# STM32WBA62xx register map
File version: 1.0
Registers are 32-bit, read-write, reset 0x0 unless marked. A register's access mark holds for its fields unless they carry their own. Offsets are from the block's base; [hi:lo] are bit positions; {n}, {i} and the like mark numbered series.

## USB_OTG_HS — USB_OTG_Core_Registers
Base 0x42040000
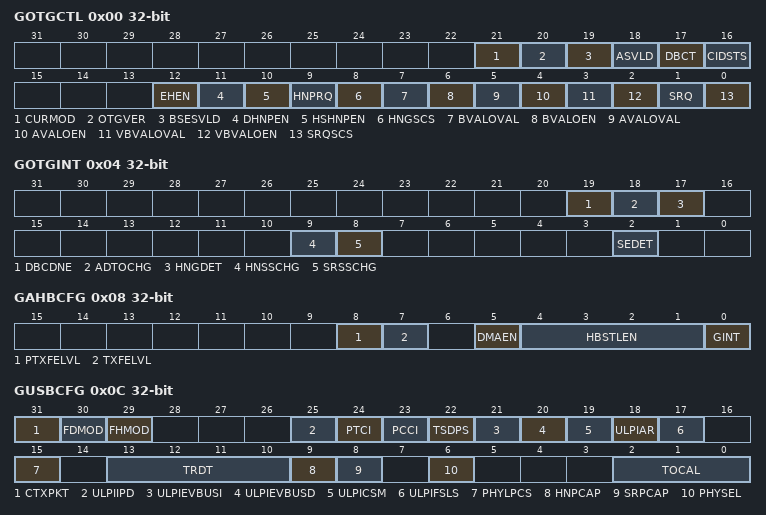
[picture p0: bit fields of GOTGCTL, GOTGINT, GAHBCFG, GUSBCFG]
0x00 GOTGCTL — USB_OTG Control and Status Register 000h
  [21] CURMOD — Current mode of operation
  [20] OTGVER — OTG version
  [19] BSESVLD — B-session valid
  [18] ASVLD — A-session valid
  [17] DBCT — Long/short debounce time
  [16] CIDSTS — Connector ID status
  [12] EHEN — Embedded host enable
  [11] DHNPEN — Device HNP enabled
  [10] HSHNPEN — Host set HNP enable
  [9] HNPRQ — HNP request
  [8] HNGSCS — Host set HNP enable
  [7] BVALOVAL — B-peripheral session valid override value
  [6] BVALOEN — B-peripheral session valid override enable
  [5] AVALOVAL — A-peripheral session valid override value
  [4] AVALOEN — A-peripheral session valid override enable
  [3] VBVALOVAL — VBUS valid override value
  [2] VBVALOEN — VBUS valid override enable
  [1] SRQ — Session request
  [0] SRQSCS — Session request success
0x04 GOTGINT — USB_OTG Interrupt Register 004h
  [19] DBCDNE — Debounce done
  [18] ADTOCHG — A-device timeout change
  [17] HNGDET — Host negotiation detected
  [9] HNSSCHG — Host negotiation success status change
  [8] SRSSCHG — Session request success status change
  [2] SEDET — Session end detected
0x08 GAHBCFG — Core AHB Configuration Register 008h
  [8] PTXFELVL — Periodic TxFIFO empty level
  [7] TXFELVL — TxFIFO empty level
  [5] DMAEN — DMA enable
  [4:1] HBSTLEN — Burst length/type
  [0] GINT — Global interrupt mask
0x0C GUSBCFG — Core USB Configuration Register 00Ch
  [31] CTXPKT — Corrupt Tx packet for debug propose only; must be kept at reset value
  [30] FDMOD — Forced peripheral mode
  [29] FHMOD — Forced host mode
  [25] ULPIIPD — ULPI interface protect disable
  [24] PTCI — Indicator pass through
  [23] PCCI — Indicator complement
  [22] TSDPS — TermSel DLine pulsing selection
  [21] ULPIEVBUSI — ULPI external VBUS indicator
  [20] ULPIEVBUSD — ULPI External VBUS Drive
  [19] ULPICSM — ULPI Clock SuspendM
  [18] ULPIAR — ULPI Auto-resume
  [17] ULPIFSLS — ULPI FS/LS select
  [15] PHYLPCS — PHY Low-power clock select
  [13:10] TRDT — USB turnaround time
  [9] HNPCAP — HNP-capable
  [8] SRPCAP — SRP-capable
  [6] PHYSEL — USB 2.0 high-speed ULPI PHY or USB 1.1 full-speed serial transceiver select
  [2:0] TOCAL — FS timeout calibration
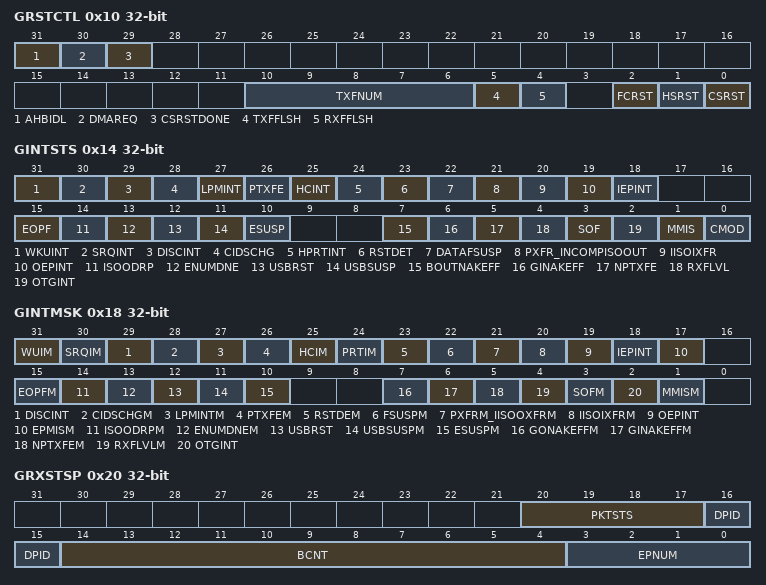
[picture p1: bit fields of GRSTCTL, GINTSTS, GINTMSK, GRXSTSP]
0x10 GRSTCTL — Core Reset Register 010h
  [31] AHBIDL — AHB master idle
  [30] DMAREQ — DMA request signal
  [29] CSRSTDONE — Core soft reset done
  [10:6] TXFNUM — TxFIFO number
  [5] TXFFLSH — TxFIFO flush
  [4] RXFFLSH — RxFIFO flush
  [2] FCRST — Host frame counter reset
  [1] HSRST — HCLK soft reset
  [0] CSRST — Core soft reset
0x14 GINTSTS — Core Interrupt Register 014h
  [31] WKUINT — Resume/remote wakeup detected interrupt
  [30] SRQINT — Session request/new session detected interrupt
  [29] DISCINT — Disconnect detected interrupt
  [28] CIDSCHG — Connector ID status change
  [27] LPMINT — LPM interrupt
  [26] PTXFE — Periodic TxFIFO empty
  [25] HCINT — Host channels interrupt
  [24] HPRTINT — Host port interrupt
  [23] RSTDET — Reset detected interrupt
  [22] DATAFSUSP — Data fetch suspended
  [21] PXFR_INCOMPISOOUT — Incomplete periodic transfer
  [20] IISOIXFR — Incomplete isochronous IN transfer
  [19] OEPINT — OUT endpoint interrupt
  [18] IEPINT — IN endpoint interrupt
  [15] EOPF — End of periodic frame interrupt
  [14] ISOODRP — Isochronous OUT packet dropped interrupt
  [13] ENUMDNE — Enumeration done
  [12] USBRST — USB reset
  [11] USBSUSP — USB suspend
  [10] ESUSP — Early suspend
  [7] BOUTNAKEFF — Global OUT NAK effective
  [6] GINAKEFF — Global IN nonperiodic NAK effective
  [5] NPTXFE — Nonperiodic TxFIFO empty
  [4] RXFLVL — RxFIFO nonempty
  [3] SOF — Start of frame
  [2] OTGINT — OTG interrupt
  [1] MMIS — Mode mismatch interrupt
  [0] CMOD — Current mode of operation
0x18 GINTMSK — Core Interrupt Mask Register 018h
  [31] WUIM — Resume/remote wakeup detected interrupt mask
  [30] SRQIM — Session request/new session detected interrupt mask
  [29] DISCINT — Disconnect detected interrupt mask
  [28] CIDSCHGM — Connector ID status change mask
  [27] LPMINTM — LPM interrupt Mask
  [26] PTXFEM — Periodic TxFIFO empty mask
  [25] HCIM — Host channels interrupt mask
  [24] PRTIM — Host port interrupt mask
  [23] RSTDEM — Reset detected interrupt mask
  [22] FSUSPM — Data fetch suspended mask
  [21] PXFRM_IISOOXFRM — Incomplete periodic transfer mask
  [20] IISOIXFRM — Incomplete isochronous IN transfer mask
  [19] OEPINT — OUT endpoints interrupt mask
  [18] IEPINT — IN endpoints interrupt mask
  [17] EPMISM — Endpoint mismatch interrupt mask
  [15] EOPFM — End of periodic frame interrupt mask
  [14] ISOODRPM — Isochronous OUT packet dropped interrupt mask
  [13] ENUMDNEM — Enumeration done mask
  [12] USBRST — USB reset mask
  [11] USBSUSPM — USB suspend mask
  [10] ESUSPM — Early suspend mask
  [7] GONAKEFFM — Global OUT NAK effective mask
  [6] GINAKEFFM — Global nonperiodic IN NAK effective mask
  [5] NPTXFEM — Nonperiodic TxFIFO empty mask
  [4] RXFLVLM — Receive FIFO nonempty mask
  [3] SOFM — Start of frame mask
  [2] OTGINT — OTG interrupt mask
  [1] MMISM — Mode mismatch interrupt mask
0x1C GRXSTSR — Receive Sts Q Read Register 01Ch
0x20 GRXSTSP — Receive Sts Q Read & POP Register 020h
  [20:17] PKTSTS — OUT EP interrupt mask bits
  [16:15] DPID — OUT EP interrupt mask bits
  [14:4] BCNT — OUT EP interrupt mask bits
  [3:0] EPNUM — IN EP interrupt mask bits
0x24 GRXFSIZ — Receive FIFO Size Register 024h
  [15:0] RXFD — RxFIFO depth
0x28 DIEPTXF0_HNPTXFSIZ — EP0 / Non Periodic Tx FIFO Size Register 028h
0x2C HNPTXSTS — Non Periodic Tx FIFO/Queue Sts reg 02Ch
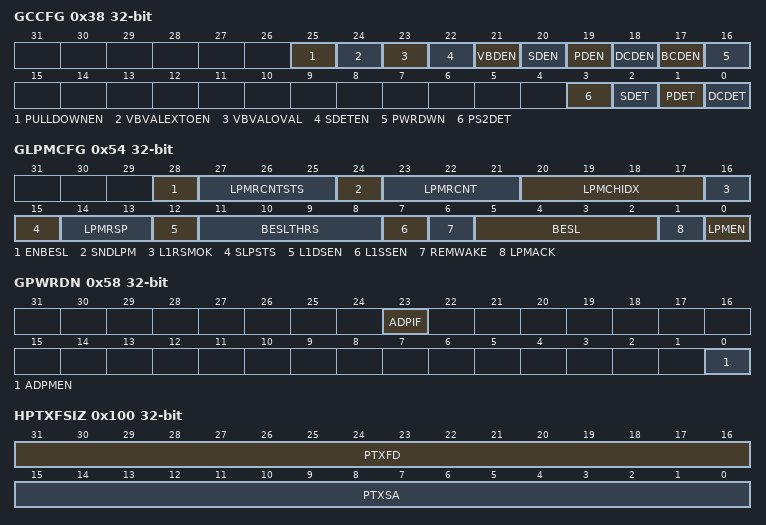
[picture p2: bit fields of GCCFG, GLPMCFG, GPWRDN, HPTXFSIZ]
0x38 GCCFG — General Purpose IO Register 038h
  [25] PULLDOWNEN — Enables of femtoPHY pulldown resistors, used when ID PAD is disabled
  [24] VBVALEXTOEN — Enables of VBUSVLDEXT0 femtoPHY input override
  [23] VBVALOVAL — Value of VBUSVLDEXT0 femtoPHY input
  [22] SDETEN — Secondary detection (PD) mode enable
  [21] VBDEN — Vbus detection enable
  [20] SDEN — Secondary detection (SD) mode enable
  [19] PDEN — Primary detection (PD) mode enable
  [18] DCDEN — Data contact detection (DCD) mode enable
  [17] BCDEN — Battery charging detector (BCD) enable
  [16] PWRDWN — Power down
  [3] PS2DET — DM pull-up detection status
  [2] SDET — Secondary detection (SD) status
  [1] PDET — Primary detection (PD) status
  [0] DCDET — Data contact detection (DCD) status
0x3C CID — User ID Register 03Ch
  [31:0] PRODUCT_ID
0x40 GSNPSID
0x54 GLPMCFG — LPM Register 054h
  [28] ENBESL — Enable best effort service latency
  [27:25] LPMRCNTSTS — LPM retry count status
  [24] SNDLPM — Send LPM transaction
  [23:21] LPMRCNT — LPM retry count
  [20:17] LPMCHIDX — LPM Channel Index
  [16] L1RSMOK — Sleep State Resume OK
  [15] SLPSTS — Port sleep status
  [14:13] LPMRSP — LPM response
  [12] L1DSEN — L1 deep sleep enable
  [11:8] BESLTHRS — BESL threshold
  [7] L1SSEN — L1 shallow sleep enable
  [6] REMWAKE — bRemoteWake value received with last ACKed LPM Token
  [5:2] BESL — BESL value received with last ACKed LPM Token
  [1] LPMACK — LPM Token acknowledge enable
  [0] LPMEN — LPM support enable
0x58 GPWRDN — Power Down Register 058h
  [23] ADPIF — ADP Interrupt flag
  [0] ADPMEN — ADP module enable
0x5C GDFIFOCFG — DFIFO Software Config Register 05Ch
0x100 HPTXFSIZ — Host Periodic Tx FIFO Size Reg 100h
  [31:16] PTXFD — Host periodic TxFIFO depth
  [15:0] PTXSA — Host periodic TxFIFO start address
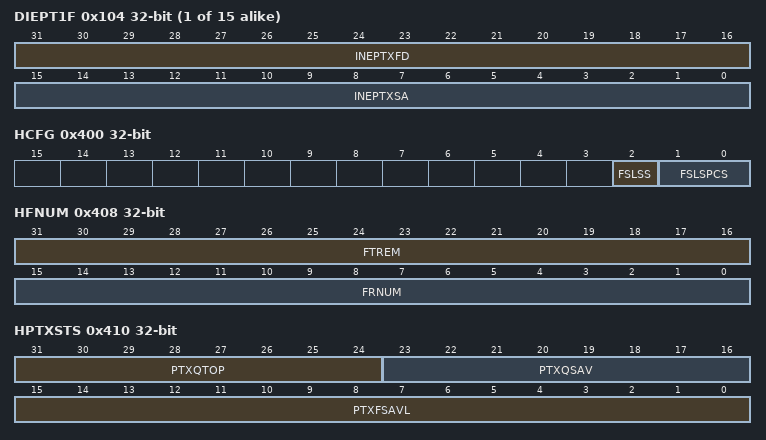
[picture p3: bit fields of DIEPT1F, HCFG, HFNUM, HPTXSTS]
{0x100+4i} DIEPT{i}F (i=1..15) — dev Periodic Transmit FIFO 104h
  [31:16] INEPTXFD — IN endpoint TxFIFO depth
  [15:0] INEPTXSA — IN endpoint FIFOx transmit RAM start address
0x400 HCFG — Host Configuration Register 400h
  [2] FSLSS — FS- and LS-only support
  [1:0] FSLSPCS — FS/LS PHY clock select
0x404 HFIR — Host Frame Interval Register 404h
  [15:0] FRIVL — Frame interval
0x408 HFNUM — Host Frame Nbr/Frame Remaining 408h
  [31:16] FTREM — Frame time remaining
  [15:0] FRNUM — Frame number
0x410 HPTXSTS — Host Periodic Tx FIFO/ Queue Status 410h
  [31:24] PTXQTOP — Top of the periodic transmit request queue
  [23:16] PTXQSAV — Periodic transmit request queue space available
  [15:0] PTXFSAVL — Periodic transmit data FIFO space available
0x414 HAINT — Host All Channels Interrupt Register 414h
  [15:0] HAINT — Channel interrupts
0x418 HAINTMSK — Host All Channels Interrupt Mask 418h
  [15:0] HAINTM — Channel interrupt mask
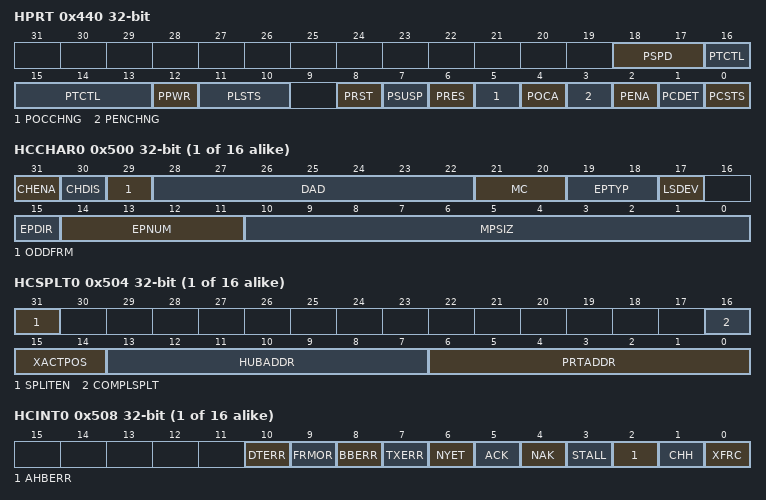
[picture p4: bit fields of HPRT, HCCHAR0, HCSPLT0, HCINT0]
0x440 HPRT
  [18:17] PSPD — Port speed
  [16:13] PTCTL — Port test control
  [12] PPWR — Port power
  [11:10] PLSTS — Port line status
  [8] PRST — Port reset
  [7] PSUSP — Port suspend
  [6] PRES — Port resume
  [5] POCCHNG — Port overcurrent change
  [4] POCA — Port overcurrent active
  [3] PENCHNG — Port enable/disable change
  [2] PENA — Port enable
  [1] PCDET — Port connect detected
  [0] PCSTS — Port connect status
{0x500+0x20*i} HCCHAR{i} (i=0..15) — Host Channel Characteristics Register 500h
  [31] CHENA — Channel enable
  [30] CHDIS — Channel disable
  [29] ODDFRM — Odd frame
  [28:22] DAD — Device address
  [21:20] MC — Multi Count (MC) / Error Count (EC)
  [19:18] EPTYP — Endpoint type
  [17] LSDEV — Low-speed device
  [15] EPDIR — Endpoint direction
  [14:11] EPNUM — Endpoint number
  [10:0] MPSIZ — Maximum packet size
{0x504+0x20*i} HCSPLT{i} (i=0..15) — Host Channel Split Control Register 504h
  [31] SPLITEN — Split enable
  [16] COMPLSPLT — Do complete split
  [15:14] XACTPOS
  [13:7] HUBADDR — Hub address
  [6:0] PRTADDR — Port address
{0x508+0x20*i} HCINT{i} (i=0..15) — Host Channel Interrupt Register 508h
  [10] DTERR — Data toggle error
  [9] FRMOR — Frame overrun
  [8] BBERR — Babble error
  [7] TXERR — Transaction error
  [6] NYET — Response received interrupt
  [5] ACK — ACK response received/transmitted interrupt
  [4] NAK — NAK response received interrupt
  [3] STALL — STALL response received interrupt
  [2] AHBERR — AHB error
  [1] CHH — Channel halted
  [0] XFRC — Transfer completed
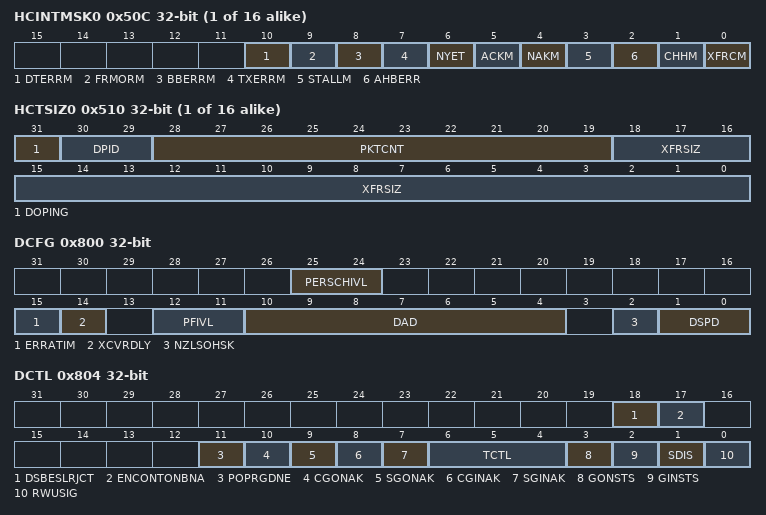
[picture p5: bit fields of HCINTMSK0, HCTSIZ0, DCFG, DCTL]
{0x50C+0x20*i} HCINTMSK{i} (i=0..15) — Host Channel Interrupt Mask Register 50Ch
  [10] DTERRM — Data toggle error mask
  [9] FRMORM — Frame overrun mask
  [8] BBERRM — Babble error mask
  [7] TXERRM — Transaction error mask
  [6] NYET — response received interrupt mask
  [5] ACKM — ACK response received/transmitted interrupt mask
  [4] NAKM — NAK response received interrupt mask
  [3] STALLM — STALL response received interrupt mask
  [2] AHBERR — AHB error
  [1] CHHM — Channel halted mask
  [0] XFRCM — Transfer completed mask
{0x510+0x20*i} HCTSIZ{i} (i=0..15) — Host Channel Transfer Size Register 510h
  [31] DOPING
  [30:29] DPID — Data PID
  [28:19] PKTCNT — Packet count
  [18:0] XFRSIZ — Transfer size
{0x514+0x20*i} HCDMA{i} (i=0..15) — Host Channel DMA Address Register 514h
  [31:0] DMAADDR — DMA address
0x800 DCFG — dev Configuration Register 800h
  [25:24] PERSCHIVL — Periodic scheduling interval
  [15] ERRATIM — Erratic error interrupt mask
  [14] XCVRDLY — Transceiver delay
  [12:11] PFIVL — Periodic (micro)frame interval
  [10:4] DAD — Device address
  [2] NZLSOHSK — Nonzero-length status OUT handshake
  [1:0] DSPD — Device speed
0x804 DCTL — dev Control Register 804h
  [18] DSBESLRJCT — Deep sleep BESL reject
  [17] ENCONTONBNA — Enable continue on BNA
  [11] POPRGDNE — Power-on programming done
  [10] CGONAK — Clear global OUT NAK
  [9] SGONAK — Set global OUT NAK
  [8] CGINAK — Clear global IN NAK
  [7] SGINAK — Set global IN NAK
  [6:4] TCTL — Test control
  [3] GONSTS — Global OUT NAK status
  [2] GINSTS — Global IN NAK status
  [1] SDIS — Soft disconnect
  [0] RWUSIG — Remote wakeup signaling
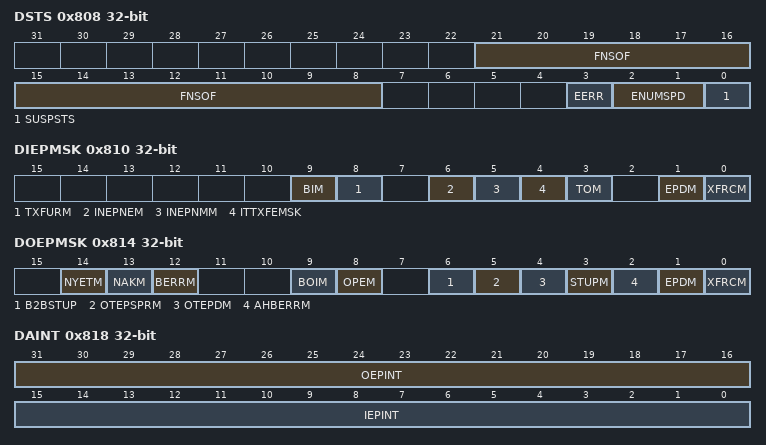
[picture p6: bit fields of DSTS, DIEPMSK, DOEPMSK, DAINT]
0x808 DSTS — dev Status Register (RO) 808h
  [21:8] FNSOF — Frame number of the received SOF
  [3] EERR — Erratic error
  [2:1] ENUMSPD — Enumerated speed
  [0] SUSPSTS — Suspend status
0x810 DIEPMSK — dev IN Endpoint Mask 810h
  [9] BIM — BNA interrupt mask
  [8] TXFURM — FIFO underrun mask
  [6] INEPNEM — IN endpoint NAK effective mask
  [5] INEPNMM — IN token received with EP mismatch mask
  [4] ITTXFEMSK — IN token received when TxFIFO empty mask
  [3] TOM — Timeout condition mask (nonisochronous endpoints)
  [1] EPDM — Endpoint disabled interrupt mask
  [0] XFRCM — Transfer completed interrupt mask
0x814 DOEPMSK — dev OUT Endpoint Mask 814h
  [14] NYETM — NYET interrupt mask
  [13] NAKM — OUT Packet NAK interrupt mask
  [12] BERRM — Babble error interrupt mask
  [9] BOIM — BNA interrupt mask
  [8] OPEM — OUT packet error mask
  [6] B2BSTUP — Back-to-back SETUP packets received mask
  [5] OTEPSPRM — Status Phase Received mask
  [4] OTEPDM — OUT token received when endpoint disabled mask
  [3] STUPM — SETUP phase done mask
  [2] AHBERRM — OUT transaction AHB Error interrupt mask
  [1] EPDM — Endpoint disabled interrupt mask
  [0] XFRCM — Transfer completed interrupt mask
0x818 DAINT — dev All Endpoints Itr Reg 818h
  [31:16] OEPINT — OUT endpoint interrupt bits
  [15:0] IEPINT — IN endpoint interrupt bits
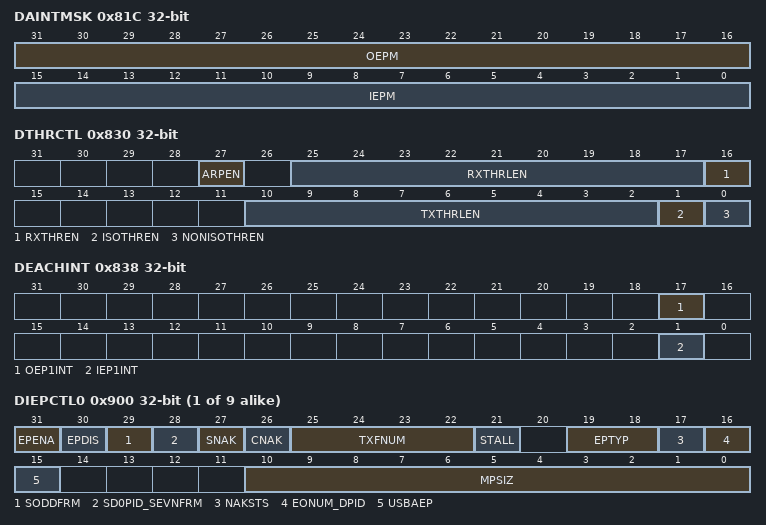
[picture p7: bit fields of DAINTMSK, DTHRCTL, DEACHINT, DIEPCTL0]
0x81C DAINTMSK — dev All Endpoints Itr Mask 81Ch
  [31:16] OEPM — OUT EP interrupt mask bits
  [15:0] IEPM — IN EP interrupt mask bits
0x828 DVBUSDIS — dev VBUS discharge Register 828h
  [15:0] VBUSDT — Device VBUS discharge time
0x82C DVBUSPULSE — dev VBUS Pulse Register 82Ch
  [11:0] DVBUSP — Device VBUS pulsing time
0x830 DTHRCTL — dev threshold 830h
  [27] ARPEN — Arbiter parking enable
  [25:17] RXTHRLEN — Receive threshold length
  [16] RXTHREN — Receive threshold enable
  [10:2] TXTHRLEN — Transmit threshold length
  [1] ISOTHREN — ISO IN endpoint threshold enable
  [0] NONISOTHREN — Nonisochronous IN endpoints threshold enable
0x834 DIEPEMPMSK — dev empty msk 834h
  [15:0] INEPTXFEM — IN EP Tx FIFO empty interrupt mask bits
0x838 DEACHINT — dedicated EP interrupt 838h
  [17] OEP1INT — OUT endpoint 1 interrupt bit
  [1] IEP1INT — IN endpoint 1interrupt bit
0x83C DEACHMSK — dedicated EP msk 83Ch
0x844 DINEP1MSK — dedicated EP mask 844h
0x884 DOUTEP1MSK — dedicated EP msk 884h
{0x900+0x20*i} DIEPCTL{i} (i=0..8) — dev IN Endpoint Control Reg 900h + (ep_num 20h) + 00h
  [31] EPENA — Endpoint enable
  [30] EPDIS — Endpoint disable
  [29] SODDFRM — Set odd frame
  [28] SD0PID_SEVNFRM — Set DATA0 PID
  [27] SNAK — Set NAK
  [26] CNAK — Clear NAK
  [25:22] TXFNUM — TxFIFO number
  [21] STALL — STALL handshake
  [19:18] EPTYP — Endpoint type
  [17] NAKSTS — NAK status
  [16] EONUM_DPID — Even/odd frame
  [15] USBAEP — USB active endpoint
  [10:0] MPSIZ — Maximum packet size
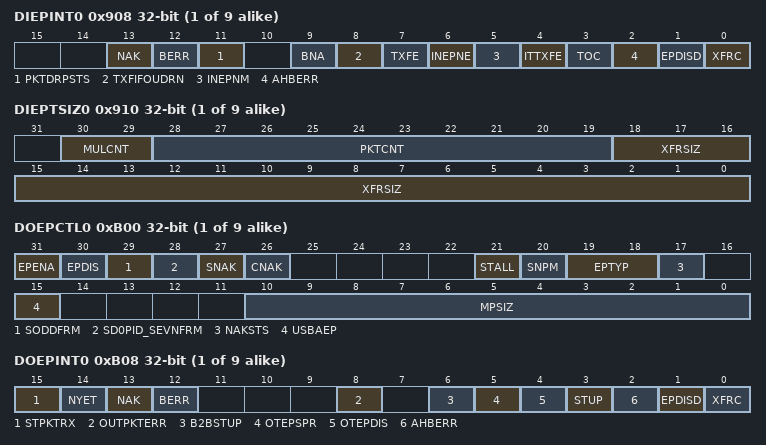
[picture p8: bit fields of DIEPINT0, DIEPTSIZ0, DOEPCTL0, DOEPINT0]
{0x908+0x20*i} DIEPINT{i} (i=0..8) — dev IN Endpoint Itr Reg 900h + (ep_num 20h) + 08h
  [13] NAK — NAK interrupt
  [12] BERR — Babble error interrupt
  [11] PKTDRPSTS — Packet dropped status
  [9] BNA — Buffer not available interrupt
  [8] TXFIFOUDRN — Transmit Fifo Underrun
  [7] TXFE — Transmit FIFO empty
  [6] INEPNE — IN endpoint NAK effective
  [5] INEPNM — IN token received with EP mismatch
  [4] ITTXFE — IN token received when TxFIFO is empty
  [3] TOC — Timeout condition
  [2] AHBERR — AHB Error (AHBErr) during an IN transaction
  [1] EPDISD — Endpoint disabled interrupt
  [0] XFRC — Transfer completed interrupt
{0x910+0x20*i} DIEPTSIZ{i} (i=0..8) — IN Endpoint Txfer Size 900h + (ep_num 20h) + 10h
  [30:29] MULCNT — Packet count
  [28:19] PKTCNT — Packet count
  [18:0] XFRSIZ — Transfer size
{0x914+0x20*i} DIEPDMA{i} (i=0..8) — IN Endpoint DMA Address Reg 900h + (ep_num 20h) + 14h
  [31:0] DMAADDR — DMA address
{0x918+0x20*i} DTXFSTS{i} (i=0..8) — IN Endpoint Tx FIFO Status Reg 900h + (ep_num 20h) + 18h
  [15:0] INEPTFSAV — IN endpoint TxFIFO space available
{0xB00+0x20*i} DOEPCTL{i} (i=0..8) — dev OUT Endpoint Control Reg B00h + (ep_num 20h) + 00h
  [31] EPENA — Endpoint enable
  [30] EPDIS — Endpoint disable
  [29] SODDFRM — Set odd frame
  [28] SD0PID_SEVNFRM — Set DATA0 PID
  [27] SNAK — Set NAK
  [26] CNAK — Clear NAK
  [21] STALL — STALL handshake
  [20] SNPM — Snoop mode
  [19:18] EPTYP — Endpoint type
  [17] NAKSTS — NAK status
  [15] USBAEP — USB active endpoint
  [10:0] MPSIZ — Maximum packet size
{0xB08+0x20*i} DOEPINT{i} (i=0..8) — dev OUT Endpoint Itr Reg B00h + (ep_num 20h) + 08h
  [15] STPKTRX — Setup Packet Received
  [14] NYET — NYET interrupt
  [13] NAK — NAK Packet is transmitted by the device
  [12] BERR — Babble error interrupt
  [8] OUTPKTERR — OUT packet error
  [6] B2BSTUP — Back-to-back SETUP packets received
  [5] OTEPSPR — OUT Status Phase Received interrupt
  [4] OTEPDIS — OUT token received when endpoint disabled
  [3] STUP — SETUP phase done
  [2] AHBERR — AHB Error (AHBErr) during an OUT transaction
  [1] EPDISD — Endpoint disabled interrupt
  [0] XFRC — Transfer completed interrupt
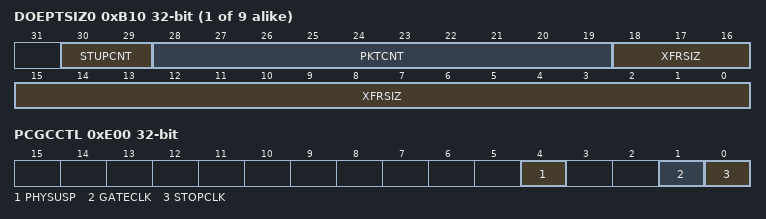
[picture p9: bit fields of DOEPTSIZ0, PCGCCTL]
{0xB10+0x20*i} DOEPTSIZ{i} (i=0..8) — dev OUT Endpoint Txfer Size B00h + (ep_num 20h) + 10h
  [30:29] STUPCNT — SETUP packet count
  [28:19] PKTCNT — Packet count
  [18:0] XFRSIZ — Transfer size
{0xB14+0x20*i} DOEPDMA{i} (i=0..8) — dev OUT Endpoint DMA Address B00h + (ep_num 20h) + 14h
0xE00 PCGCCTL
  [4] PHYSUSP — Bit 1
  [1] GATECLK — Bit 0
  [0] STOPCLK — SETUP packet count
